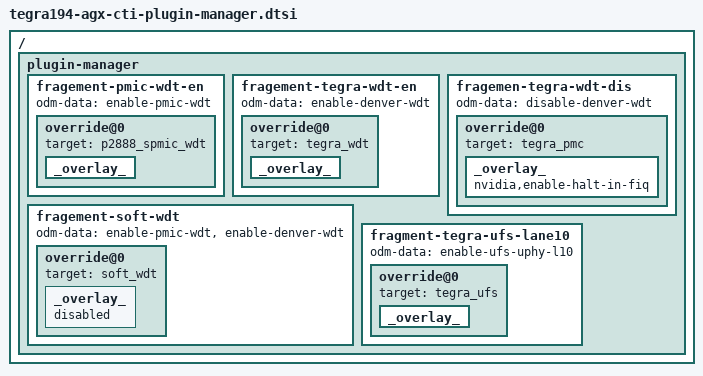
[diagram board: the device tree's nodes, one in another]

/ {
	plugin-manager {
		fragement-pmic-wdt-en {
			odm-data = "enable-pmic-wdt";
			override@0 {
				target = <&p2888_spmic_wdt>;
				_overlay_ {
					status = "okay";
				};
			};
		};

		fragement-tegra-wdt-en {
			odm-data = "enable-denver-wdt";
			override@0 {
				target = <&tegra_wdt>;
				_overlay_ {
					status = "okay";
				};
			};
		};

		fragemen-tegra-wdt-dis {
			odm-data = "disable-denver-wdt";
			override@0 {
				target = <&tegra_pmc>;
				_overlay_ {
					nvidia,enable-halt-in-fiq;
				};
			};
		};

        fragement-soft-wdt {
            odm-data = "enable-pmic-wdt",
                   "enable-denver-wdt";
            override@0 {
                target = <&soft_wdt>;
                _overlay_ {
                    status = "disabled";
                };
            };
        };

		fragment-tegra-ufs-lane10 {
			odm-data = "enable-ufs-uphy-l10";
			override@0 {
				target = <&tegra_ufs>;
				_overlay_ {
					status = "okay";
				};
			};
		};
	};
};
